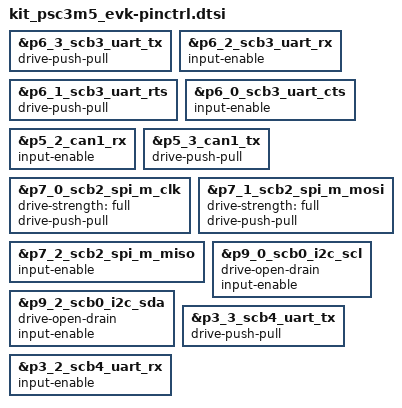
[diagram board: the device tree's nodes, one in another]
/*
 * Copyright (c) 2025 Cypress Semiconductor Corporation.
 * SPDX-License-Identifier: Apache-2.0
 */

/* Configure pin drive mode for uart pins */
&p6_3_scb3_uart_tx {
	drive-push-pull;
};

&p6_2_scb3_uart_rx {
	input-enable;
};

&p6_1_scb3_uart_rts {
	drive-push-pull;
};

&p6_0_scb3_uart_cts {
	input-enable;
};

/* Configure pin drive mode for can pins */
&p5_2_can1_rx {
	input-enable;
};

&p5_3_can1_tx {
	drive-push-pull;
};

/* Configure pin drive mode for SCB2 SPI pins (MikroBUS) */
&p7_0_scb2_spi_m_clk {
	drive-strength = "full";
	drive-push-pull;
};

&p7_1_scb2_spi_m_mosi {
	drive-strength = "full";
	drive-push-pull;
};

&p7_2_scb2_spi_m_miso {
	input-enable;
};

/* Configure pin drive mode for SCB0 I2C pins (MikroBUS) */
&p9_0_scb0_i2c_scl {
	drive-open-drain;
	input-enable;
};

&p9_2_scb0_i2c_sda {
	drive-open-drain;
	input-enable;
};

/* Configure pin drive mode for SCB4 UART pins (MikroBUS) */
&p3_3_scb4_uart_tx {
	drive-push-pull;
};

&p3_2_scb4_uart_rx {
	input-enable;
};
